# f280013x_access_protection_regs register map
Vendor: Texas Instruments
Peripheral module from a debugger description file (folder C2000).
Address unit: 16 bits
Registers are 32-bit, read-only, no defined reset value unless marked. A register's access mark holds for its fields unless they carry their own. Offsets are as the file gives them; lines under a group give offsets from that group; [hi:lo] are bit positions; {n}, {i} and the like mark numbered series; 'fields as' and 'values as' point back to an identical list; <NAME> marks a mode.

## ACCESS_PROTECTION_REGS — ACCESS PROTECTION Registers
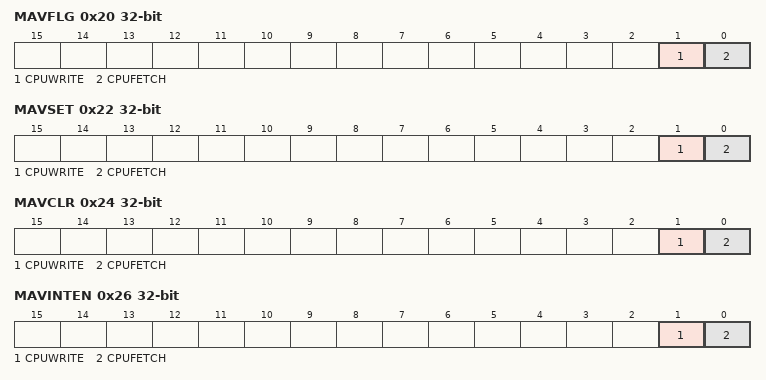
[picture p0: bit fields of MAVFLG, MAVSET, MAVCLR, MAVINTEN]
0x20 MAVFLG — Master Access Violation Flag Register
  [1] CPUWRITE — Master CPU Write Access Violation Flag
  [0] CPUFETCH — Master CPU Fetch Access Violation Flag
0x22 MAVSET rw — Master Access Violation Flag Set Register
  [1] CPUWRITE — Master CPU Write Access Violation Flag Set
  [0] CPUFETCH — Master CPU Fetch Access Violation Flag Set
0x24 MAVCLR rw — Master Access Violation Flag Clear Register
  [1] CPUWRITE — Master CPU Write Access Violation Flag Clear
  [0] CPUFETCH — Master CPU Fetch Access Violation Flag Clear
0x26 MAVINTEN rw — Master Access Violation Interrupt Enable Register
  [1] CPUWRITE — Master CPU Write Access Violation Interrupt Enable
  [0] CPUFETCH — Master CPU Fetch Access Violation Interrupt Enable
0x28 MCPUFAVADDR — Master CPU Fetch Access Violation Address
  [31:0] MCPUFAVADDR — Master CPU fetch access violation address register.
0x2A MCPUWRAVADDR — Master CPU Write Access Violation Address
  [31:0] MCPUWRAVADDR — Master CPU write access violation address register.
